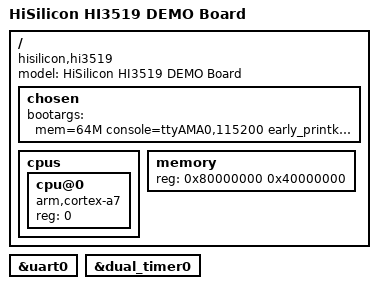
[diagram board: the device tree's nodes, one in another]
/*
 * Copyright (c) 2015 HiSilicon Technologies Co., Ltd.
 *
 * This program is free software; you can redistribute  it and/or modify it
 * under  the terms of  the GNU General  Public License as published by the
 * Free Software Foundation;  either version 2 of the  License, or (at your
 * option) any later version.
 *
 * This program is distributed in the hope that it will be useful,
 * but WITHOUT ANY WARRANTY; without even the implied warranty of
 * MERCHANTABILITY or FITNESS FOR A PARTICULAR PURPOSE. See the
 * GNU General Public License for more details.
 *
 * You should have received a copy of the GNU General Public License
 * along with this program.  If not, see <http://www.gnu.org/licenses/>.
 *
 */

/dts-v1/;
#include "hi3519.dtsi"

/ {
	model = "HiSilicon HI3519 DEMO Board";
	compatible = "hisilicon,hi3519";

	chosen {
		bootargs = "mem=64M console=ttyAMA0,115200 early_printk \
root=/dev/mtdblock2 rootfstype=jffs2 \
mtdparts=hi_sfc:1M(boot),4M(kernel),11M(rootfs)";
	};

	cpus {
		#address-cells = <1>;
		#size-cells = <0>;

		cpu@0 {
			device_type = "cpu";
			compatible = "arm,cortex-a7";
			reg = <0>;
		};
	};

	memory {
		device_type = "memory";
		reg = <0x80000000 0x40000000>;
	};
};

&uart0 {
	status = "okay";
};

&dual_timer0 {
	status = "okay";
};
